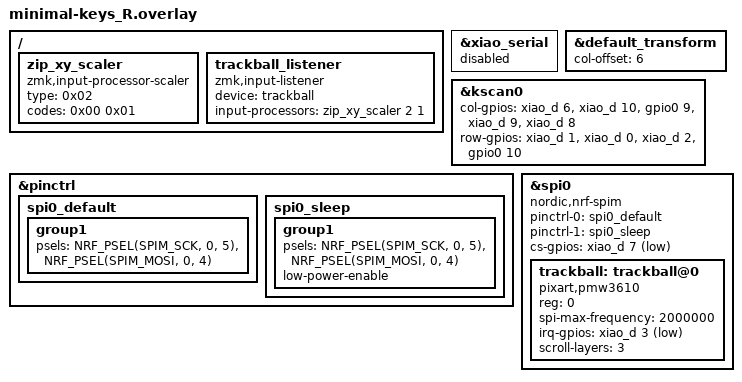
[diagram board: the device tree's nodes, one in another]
#include "minimal-keys.dtsi"

&xiao_serial { status = "disabled"; };

&default_transform {
    col-offset = <6>;
};

&kscan0 {
    col-gpios
        = <&xiao_d 6 GPIO_ACTIVE_HIGH>
        , <&xiao_d 10 GPIO_ACTIVE_HIGH>
        , <&gpio0 9 GPIO_ACTIVE_HIGH>
        , <&xiao_d 9 GPIO_ACTIVE_HIGH>
        , <&xiao_d 8 GPIO_ACTIVE_HIGH>
        ;
    row-gpios 
        = <&xiao_d 1 (GPIO_ACTIVE_HIGH | GPIO_PULL_DOWN)>
        , <&xiao_d 0 (GPIO_ACTIVE_HIGH | GPIO_PULL_DOWN)>
        , <&xiao_d 2 (GPIO_ACTIVE_HIGH | GPIO_PULL_DOWN)>
        , <&gpio0 10 (GPIO_ACTIVE_HIGH | GPIO_PULL_DOWN)>
        ;
};

&pinctrl {
    spi0_default: spi0_default {
        group1 {
            psels = <NRF_PSEL(SPIM_SCK, 0, 5)>,
                    <NRF_PSEL(SPIM_MOSI, 0, 4)>;
        };
    };

    spi0_sleep: spi0_sleep {
        group1 {
            psels = <NRF_PSEL(SPIM_SCK, 0, 5)>,
                    <NRF_PSEL(SPIM_MOSI, 0, 4)>;
            low-power-enable;
        };
    };
};

/ {
    /* 速度調整用のプロセッサ定義（定数を数値に置き換え） */
    zip_xy_scaler: zip_xy_scaler {
        compatible = "zmk,input-processor-scaler";
        #input-processor-cells = <2>;
        type = <0x02>;      /* INPUT_EV_REL */
        codes = <0x00 0x01>; /* INPUT_REL_X, INPUT_REL_Y */
    };

    trackball_listener {
        compatible = "zmk,input-listener";
        device = <&trackball>;
        /* 赤い球対策：2倍速（2 1）に設定。物足りなければ 3 1 に変更 */
        input-processors = <&zip_xy_scaler 2 1>;
    };
};

&spi0 {
    status = "okay";
    compatible = "nordic,nrf-spim";
    pinctrl-0 = <&spi0_default>;
    pinctrl-1 = <&spi0_sleep>;
    pinctrl-names = "default", "sleep";
    cs-gpios = <&xiao_d 7 GPIO_ACTIVE_LOW>;

    trackball: trackball@0 {
        status = "okay";
        compatible = "pixart,pmw3610";
        reg = <0>;
        spi-max-frequency = <2000000>;
        irq-gpios = <&xiao_d 3 (GPIO_ACTIVE_LOW | GPIO_PULL_UP)>;
        scroll-layers = <3>;
    };
};
